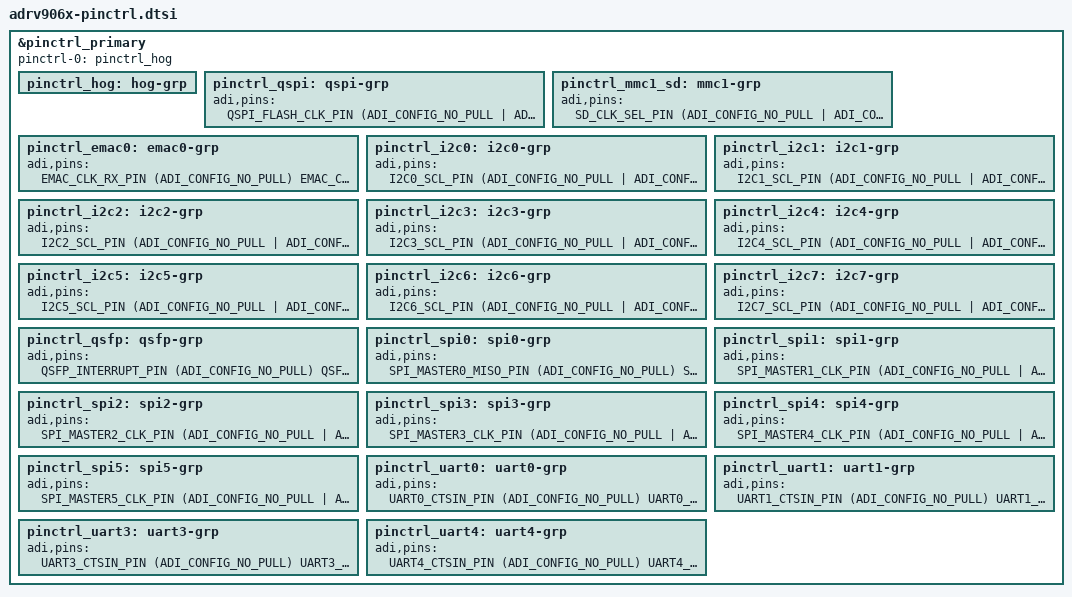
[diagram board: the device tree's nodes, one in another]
// SPDX-License-Identifier: GPL-2.0
/*
 * Copyright (c) 2023, Analog Devices Incorporated, All Rights Reserved
 */

#include <dt-bindings/pinctrl/pinctrl-adi-adrv906x-io-pad.h>
#include "adrv906x_def.h"

&pinctrl_primary {
	pinctrl-names = "default";
	pinctrl-0 = <&pinctrl_hog>;

	pinctrl_hog: hog-grp {
	};

	pinctrl_qspi: qspi-grp {
		adi,pins = <
		QSPI_FLASH_CLK_PIN	(ADI_CONFIG_NO_PULL                | ADI_CONFIG_DRIVE_STRENGTH_4)
		QSPI_FLASH_SELB_PIN	(ADI_CONFIG_ENABLE_PULLUP          | ADI_CONFIG_DRIVE_STRENGTH_4)
		QSPI_FLASH_D0_PIN	(ADI_CONFIG_ENABLE_SCHMITT_TRIGGER | ADI_CONFIG_DRIVE_STRENGTH_4)
		QSPI_FLASH_D1_PIN	(ADI_CONFIG_ENABLE_SCHMITT_TRIGGER | ADI_CONFIG_DRIVE_STRENGTH_4)
		QSPI_FLASH_D2_PIN	(ADI_CONFIG_ENABLE_SCHMITT_TRIGGER | ADI_CONFIG_DRIVE_STRENGTH_4)
		QSPI_FLASH_D3_PIN	(ADI_CONFIG_ENABLE_SCHMITT_TRIGGER | ADI_CONFIG_DRIVE_STRENGTH_4)
		A55_GPIO_NS_84_PIN	(ADI_CONFIG_ENABLE_PULLUP          | ADI_CONFIG_DRIVE_STRENGTH_4)
		>;
	};

	pinctrl_mmc1_sd: mmc1-grp {
	adi,pins = <
		SD_CLK_SEL_PIN		(ADI_CONFIG_NO_PULL                | ADI_CONFIG_DRIVE_STRENGTH_4)
		SD_CMD_PIN		(ADI_CONFIG_ENABLE_SCHMITT_TRIGGER | ADI_CONFIG_DRIVE_STRENGTH_4)
		SD_DATA0_PIN		(ADI_CONFIG_ENABLE_SCHMITT_TRIGGER | ADI_CONFIG_DRIVE_STRENGTH_4)
		SD_DATA1_PIN		(ADI_CONFIG_ENABLE_SCHMITT_TRIGGER | ADI_CONFIG_DRIVE_STRENGTH_4)
		SD_DATA2_PIN		(ADI_CONFIG_ENABLE_SCHMITT_TRIGGER | ADI_CONFIG_DRIVE_STRENGTH_4)
		SD_DATA3_PIN		(ADI_CONFIG_ENABLE_SCHMITT_TRIGGER | ADI_CONFIG_DRIVE_STRENGTH_4)
		SD_CARDDETECT_PIN	(ADI_CONFIG_ENABLE_SCHMITT_TRIGGER | ADI_CONFIG_DRIVE_STRENGTH_4)
		>;
	};

	pinctrl_emac0: emac0-grp {
		adi,pins = <
		EMAC_CLK_RX_PIN		(ADI_CONFIG_NO_PULL)
		EMAC_CLK_TX_PIN		(ADI_CONFIG_NO_PULL  | ADI_CONFIG_DRIVE_STRENGTH_4)
		EMAC_GMII_MDC_PIN	(ADI_CONFIG_NO_PULL  | ADI_CONFIG_DRIVE_STRENGTH_4)
		EMAC_GMII_MDIO_PIN	(ADI_CONFIG_NO_PULL  | ADI_CONFIG_DRIVE_STRENGTH_4)
		EMAC_PHY_INTR_PIN	(ADI_CONFIG_NO_PULL)
		EMAC_PHY_RXD_0_PIN	(ADI_CONFIG_NO_PULL)
		EMAC_PHY_RXD_1_PIN	(ADI_CONFIG_NO_PULL)
		EMAC_PHY_RXD_2_PIN	(ADI_CONFIG_NO_PULL)
		EMAC_PHY_RXD_3_PIN	(ADI_CONFIG_NO_PULL)
		EMAC_PHY_RX_DV_PIN	(ADI_CONFIG_NO_PULL)
		EMAC_PHY_TXD_0_PIN	(ADI_CONFIG_NO_PULL  | ADI_CONFIG_DRIVE_STRENGTH_4)
		EMAC_PHY_TXD_1_PIN	(ADI_CONFIG_NO_PULL  | ADI_CONFIG_DRIVE_STRENGTH_4)
		EMAC_PHY_TXD_2_PIN	(ADI_CONFIG_NO_PULL  | ADI_CONFIG_DRIVE_STRENGTH_4)
		EMAC_PHY_TXD_3_PIN	(ADI_CONFIG_NO_PULL  | ADI_CONFIG_DRIVE_STRENGTH_4)
		EMAC_PHY_TXEN_PIN	(ADI_CONFIG_NO_PULL  | ADI_CONFIG_DRIVE_STRENGTH_4)
		A55_GPIO_NS_88_PIN	(ADI_CONFIG_NO_PULL  | ADI_CONFIG_DRIVE_STRENGTH_4)
		>;
	};

	pinctrl_i2c0: i2c0-grp {
		adi,pins = <
		I2C0_SCL_PIN	(ADI_CONFIG_NO_PULL  | ADI_CONFIG_DRIVE_STRENGTH_4)	/* DedicatedIO */
		I2C0_SDA_PIN	(ADI_CONFIG_NO_PULL  | ADI_CONFIG_DRIVE_STRENGTH_4)	/* DedicatedIO */
		>;
	};

	pinctrl_i2c1: i2c1-grp {
		adi,pins = <
		I2C1_SCL_PIN	(ADI_CONFIG_NO_PULL  | ADI_CONFIG_DRIVE_STRENGTH_4)
		I2C1_SDA_PIN	(ADI_CONFIG_NO_PULL  | ADI_CONFIG_DRIVE_STRENGTH_4)
		>;
	};

	pinctrl_i2c2: i2c2-grp {
		adi,pins = <
		I2C2_SCL_PIN	(ADI_CONFIG_NO_PULL  | ADI_CONFIG_DRIVE_STRENGTH_4)
		I2C2_SDA_PIN	(ADI_CONFIG_NO_PULL  | ADI_CONFIG_DRIVE_STRENGTH_4)
		>;
	};

	pinctrl_i2c3: i2c3-grp {
		adi,pins = <
		I2C3_SCL_PIN	(ADI_CONFIG_NO_PULL  | ADI_CONFIG_DRIVE_STRENGTH_4)
		I2C3_SDA_PIN	(ADI_CONFIG_NO_PULL  | ADI_CONFIG_DRIVE_STRENGTH_4)
		>;
	};

	pinctrl_i2c4: i2c4-grp {
		adi,pins = <
		I2C4_SCL_PIN	(ADI_CONFIG_NO_PULL  | ADI_CONFIG_DRIVE_STRENGTH_4)
		I2C4_SDA_PIN	(ADI_CONFIG_NO_PULL  | ADI_CONFIG_DRIVE_STRENGTH_4)
		>;
	};

	pinctrl_i2c5: i2c5-grp {
		adi,pins = <
		I2C5_SCL_PIN	(ADI_CONFIG_NO_PULL  | ADI_CONFIG_DRIVE_STRENGTH_4)
		I2C5_SDA_PIN	(ADI_CONFIG_NO_PULL  | ADI_CONFIG_DRIVE_STRENGTH_4)
		>;
	};

	pinctrl_i2c6: i2c6-grp {
		adi,pins = <
		I2C6_SCL_PIN	(ADI_CONFIG_NO_PULL  | ADI_CONFIG_DRIVE_STRENGTH_4)
		I2C6_SDA_PIN	(ADI_CONFIG_NO_PULL  | ADI_CONFIG_DRIVE_STRENGTH_4)
		>;
	};

	pinctrl_i2c7: i2c7-grp {
		adi,pins = <
		I2C7_SCL_PIN	(ADI_CONFIG_NO_PULL  | ADI_CONFIG_DRIVE_STRENGTH_4)
		I2C7_SDA_PIN	(ADI_CONFIG_NO_PULL  | ADI_CONFIG_DRIVE_STRENGTH_4)
		>;
	};

	pinctrl_qsfp: qsfp-grp {
		adi,pins = <
		QSFP_INTERRUPT_PIN	(ADI_CONFIG_NO_PULL)
		QSFP_MODPRS_0_PIN	(ADI_CONFIG_NO_PULL  | ADI_CONFIG_DRIVE_STRENGTH_4)
		QSFP_MODPRS_1_PIN	(ADI_CONFIG_NO_PULL  | ADI_CONFIG_DRIVE_STRENGTH_4)
		QSFP_MODSEL_0_PIN	(ADI_CONFIG_NO_PULL  | ADI_CONFIG_DRIVE_STRENGTH_4)
		QSFP_MODSEL_1_PIN	(ADI_CONFIG_NO_PULL  | ADI_CONFIG_DRIVE_STRENGTH_4)
		QSFP_RESET_PIN		(ADI_CONFIG_NO_PULL  | ADI_CONFIG_DRIVE_STRENGTH_4)
		>;
	};

	pinctrl_spi0: spi0-grp {
		adi,pins = <
		SPI_MASTER0_MISO_PIN	(ADI_CONFIG_NO_PULL)					/* DedicatedIO */
		SPI_MASTER0_MOSI_PIN	(ADI_CONFIG_NO_PULL  | ADI_CONFIG_DRIVE_STRENGTH_4)	/* DedicatedIO */
		SPI_MASTER0_CLK_PIN	(ADI_CONFIG_NO_PULL  | ADI_CONFIG_DRIVE_STRENGTH_4)	/* DedicatedIO */
		SPI_MASTER0_SELB_0_PIN	(ADI_CONFIG_NO_PULL  | ADI_CONFIG_DRIVE_STRENGTH_4)	/* DedicatedIO */
		SPI_MASTER0_SELB_1_PIN	(ADI_CONFIG_NO_PULL  | ADI_CONFIG_DRIVE_STRENGTH_4)
		>;
	};

	pinctrl_spi1: spi1-grp {
		adi,pins = <
		SPI_MASTER1_CLK_PIN	(ADI_CONFIG_NO_PULL  | ADI_CONFIG_DRIVE_STRENGTH_4)
		SPI_MASTER1_MISO_PIN	(ADI_CONFIG_NO_PULL)
		SPI_MASTER1_MOSI_PIN	(ADI_CONFIG_NO_PULL  | ADI_CONFIG_DRIVE_STRENGTH_4)
		SPI_MASTER1_SELB_0_PIN	(ADI_CONFIG_NO_PULL  | ADI_CONFIG_DRIVE_STRENGTH_4)
		SPI_MASTER1_SELB_1_PIN	(ADI_CONFIG_NO_PULL  | ADI_CONFIG_DRIVE_STRENGTH_4)
		SPI_MASTER1_SELB_2_PIN	(ADI_CONFIG_NO_PULL  | ADI_CONFIG_DRIVE_STRENGTH_4)
		SPI_MASTER1_SELB_3_PIN	(ADI_CONFIG_NO_PULL  | ADI_CONFIG_DRIVE_STRENGTH_4)
		>;
	};

	pinctrl_spi2: spi2-grp {
		adi,pins = <
		SPI_MASTER2_CLK_PIN	(ADI_CONFIG_NO_PULL  | ADI_CONFIG_DRIVE_STRENGTH_4)
		SPI_MASTER2_MISO_PIN	(ADI_CONFIG_NO_PULL)
		SPI_MASTER2_MOSI_PIN	(ADI_CONFIG_NO_PULL  | ADI_CONFIG_DRIVE_STRENGTH_4)
		SPI_MASTER2_SELB_PIN	(ADI_CONFIG_NO_PULL  | ADI_CONFIG_DRIVE_STRENGTH_4)
		>;
	};

	pinctrl_spi3: spi3-grp {
		adi,pins = <
		SPI_MASTER3_CLK_PIN	(ADI_CONFIG_NO_PULL  | ADI_CONFIG_DRIVE_STRENGTH_4)
		SPI_MASTER3_MISO_PIN	(ADI_CONFIG_NO_PULL)
		SPI_MASTER3_MOSI_PIN	(ADI_CONFIG_NO_PULL  | ADI_CONFIG_DRIVE_STRENGTH_4)
		SPI_MASTER3_SELB_PIN	(ADI_CONFIG_NO_PULL  | ADI_CONFIG_DRIVE_STRENGTH_4)
		>;
	};

	pinctrl_spi4: spi4-grp {
		adi,pins = <
		SPI_MASTER4_CLK_PIN	(ADI_CONFIG_NO_PULL  | ADI_CONFIG_DRIVE_STRENGTH_4)
		SPI_MASTER4_MISO_PIN	(ADI_CONFIG_NO_PULL)
		SPI_MASTER4_MOSI_PIN	(ADI_CONFIG_NO_PULL  | ADI_CONFIG_DRIVE_STRENGTH_4)
		SPI_MASTER4_SELB_PIN	(ADI_CONFIG_NO_PULL  | ADI_CONFIG_DRIVE_STRENGTH_4)
		>;
	};

	pinctrl_spi5: spi5-grp {
		adi,pins = <
		SPI_MASTER5_CLK_PIN	(ADI_CONFIG_NO_PULL  | ADI_CONFIG_DRIVE_STRENGTH_4)
		SPI_MASTER5_MISO_PIN	(ADI_CONFIG_NO_PULL)
		SPI_MASTER5_MOSI_PIN	(ADI_CONFIG_NO_PULL  | ADI_CONFIG_DRIVE_STRENGTH_4)
		SPI_MASTER5_SELB_PIN	(ADI_CONFIG_NO_PULL  | ADI_CONFIG_DRIVE_STRENGTH_4)
		>;
	};

	pinctrl_uart0: uart0-grp {
		adi,pins = <
		UART0_CTSIN_PIN		(ADI_CONFIG_NO_PULL)
		UART0_RTSOUT_PIN	(ADI_CONFIG_NO_PULL  | ADI_CONFIG_DRIVE_STRENGTH_4)
		UART0_RXSIN_PIN		(ADI_CONFIG_NO_PULL)
		UART0_TXSOUT_PIN	(ADI_CONFIG_NO_PULL  | ADI_CONFIG_DRIVE_STRENGTH_4)
		>;
	};

	pinctrl_uart1: uart1-grp {
		adi,pins = <
		UART1_CTSIN_PIN		(ADI_CONFIG_NO_PULL)
		UART1_RTSOUT_PIN	(ADI_CONFIG_NO_PULL  | ADI_CONFIG_DRIVE_STRENGTH_4)
		UART1_RXSIN_PIN		(ADI_CONFIG_NO_PULL)
		UART1_TXSOUT_PIN	(ADI_CONFIG_NO_PULL  | ADI_CONFIG_DRIVE_STRENGTH_4)
		>;
	};

	pinctrl_uart3: uart3-grp {
		adi,pins = <
		UART3_CTSIN_PIN		(ADI_CONFIG_NO_PULL)
		UART3_RTSOUT_PIN	(ADI_CONFIG_NO_PULL  | ADI_CONFIG_DRIVE_STRENGTH_4)
		UART3_RXSIN_PIN		(ADI_CONFIG_NO_PULL)
		UART3_TXSOUT_PIN	(ADI_CONFIG_NO_PULL  | ADI_CONFIG_DRIVE_STRENGTH_4)
		>;
	};

	pinctrl_uart4: uart4-grp {
		adi,pins = <
		UART4_CTSIN_PIN		(ADI_CONFIG_NO_PULL)
		UART4_RTSOUT_PIN	(ADI_CONFIG_NO_PULL  | ADI_CONFIG_DRIVE_STRENGTH_4)
		UART4_RXSIN_PIN		(ADI_CONFIG_NO_PULL)
		UART4_TXSOUT_PIN	(ADI_CONFIG_NO_PULL  | ADI_CONFIG_DRIVE_STRENGTH_4)
		>;
	};
};
